# MAX32600 register map
File version: 1.0
Registers are 32-bit, read-write, reset 0x0 unless marked. A register's access mark holds for its fields unless they carry their own. Offsets are from the block's base; [hi:lo] are bit positions; {n}, {i} and the like mark numbered series.

## DAC0 — DAC (DAC0-12bit, DAC1-12bit, DAC2-8bit, DAC3-8bit)
Base 0x40050000
Same registers: DAC1 0x40051000, DAC2 0x40052000, DAC3 0x40053000
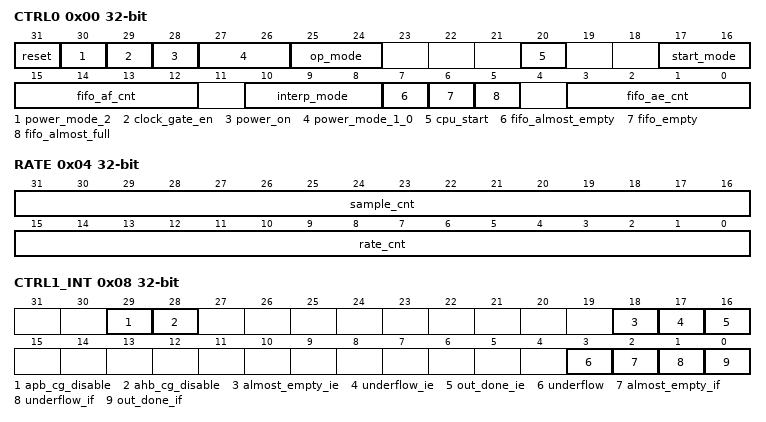
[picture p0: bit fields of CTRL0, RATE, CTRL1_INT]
0x00 CTRL0 — DAC Control Register 0
  [31] reset — DAC Reset
  [30] power_mode_2 — DAC Power Mode (bit 2)
  [29] clock_gate_en — DAC Interface Clock Gate Enable
  [28] power_on — DAC Power On Enable
  [27:26] power_mode_1_0 — DAC Power Mode (bits 1 and 0)
  [25:24] op_mode — DAC Operation Mode
  [20] cpu_start — DAC Output CPU Start
  [17:16] start_mode — DAC Output Start Mode
  [15:12] fifo_af_cnt — DAC FIFO Almost Full Threshold
  [10:8] interp_mode — DAC Output Interpolation Mode
  [7] fifo_almost_empty ro — DAC FIFO Almost Empty Flag
  [6] fifo_empty ro — DAC FIFO Empty Flag
  [5] fifo_almost_full ro — DAC FIFO Almost Full Flag
  [3:0] fifo_ae_cnt — DAC FIFO Almost Empty Threshold
0x04 RATE — DAC Output Rate/Sample Control
  [31:16] sample_cnt — DAC Output Sample Count
  [15:0] rate_cnt — DAC Output Rate Control
0x08 CTRL1_INT — DAC Control Register 1, Interrupt Flags and Enable/Disable
  [29] apb_cg_disable — Local APB dynamic clock gate disable
  [28] ahb_cg_disable — Local AHB dynamic clock gate disable
  [18] almost_empty_ie — FIFO Almost Empty Interrupt Enable
  [17] underflow_ie — FIFO Underflow Interrupt Enable
  [16] out_done_ie — DAC Output Done Interrupt Enable
  [3] underflow ro — FIFO Underflow Status
  [2] almost_empty_if write-1-clears — FIFO Almost Empty Interrupt Flag
  [1] underflow_if write-1-clears — FIFO Underflow Interrupt Flag
  [0] out_done_if write-1-clears — DAC Output Done Interrupt Flag

## ADC
Base 0x40054000
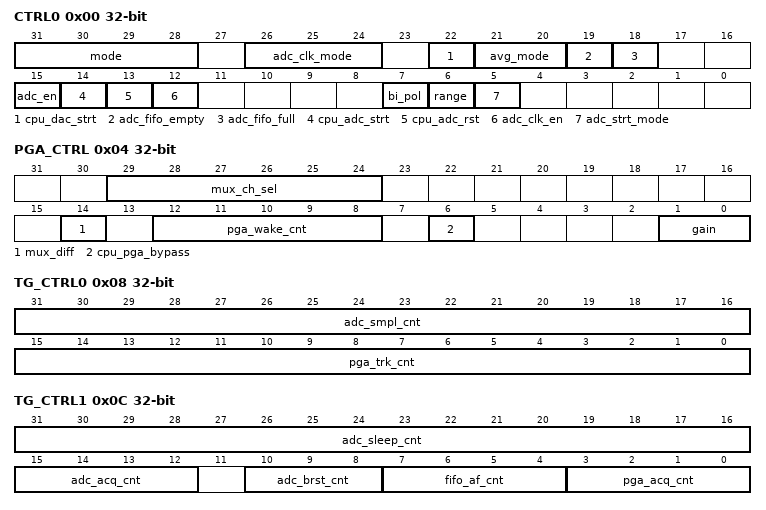
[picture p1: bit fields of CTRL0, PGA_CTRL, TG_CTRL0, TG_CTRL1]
0x00 CTRL0 — ADC Control Register 0
  [31:28] mode — ADC Operating Mode
  [26:24] adc_clk_mode — ADC Clock Mode
  [22] cpu_dac_strt — CPU DAC Sequence Start
  [21:20] avg_mode — ADC Decimation Filter Mode
  [19] adc_fifo_empty ro — ADC FIFO Empty Flag
  [18] adc_fifo_full ro — ADC FIFO Almost Full Warning
  [15] adc_en — CPU ADC Enable
  [14] cpu_adc_strt — CPU Start for ADC Data Collection
  [13] cpu_adc_rst — CPU ADC Reset
  [12] adc_clk_en — ADC Interface Clock Enable
  [7] bi_pol — ADC Unipolar/Bipolar Mode Select
  [6] range — ADC Range Control (Bipolar Mode Only)
  [5] adc_strt_mode — ADC Start Mode Control
0x04 PGA_CTRL — PGA Control Register
  [29:24] mux_ch_sel — ADC Input Mux Select
  [14] mux_diff — Differential ADC Mux Select
  [12:8] pga_wake_cnt — PGA Wakeup Counter
  [6] cpu_pga_bypass — PGA Bypass Control
  [1:0] gain — PGA Gain Setting
0x08 TG_CTRL0 — ADC Timing Generator Control 0
  [31:16] adc_smpl_cnt — ADC Sample Count
  [15:0] pga_trk_cnt — PGA Track Window Count
0x0C TG_CTRL1 — ADC Timing Generator Control 1
  [31:16] adc_sleep_cnt — ADC Sleep Count
  [15:12] adc_acq_cnt — ADC Acquisition Window Count
  [10:8] adc_brst_cnt — ADC Burst Count Setting
  [7:4] fifo_af_cnt — ADC FIFO Almost Full Threshold Control
  [3:0] pga_acq_cnt — PGA Acquisition Window Count
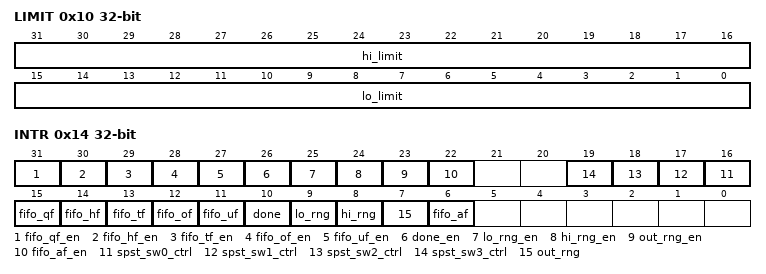
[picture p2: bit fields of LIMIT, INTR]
0x10 LIMIT — ADC Limit Settings
  [31:16] hi_limit — ADC Sample Upper Limit
  [15:0] lo_limit — ADC Sample Lower Limit
0x14 INTR — ADC Interrupt Flags and Enable/Disable Controls
  [31] fifo_qf_en — ADC FIFO One-Quarter Full Interrupt Enable
  [30] fifo_hf_en — ADC FIFO Half Full Interrupt Enable
  [29] fifo_tf_en — ADC FIFO Three-Quarters Full Interrupt Enable
  [28] fifo_of_en — ADC FIFO Overflow Interrupt Enable
  [27] fifo_uf_en — ADC FIFO Underflow Interrupt Enable
  [26] done_en — ADC Data Collection Complete Interrupt Enable
  [25] lo_rng_en — ADC Sample Below Low Limit Interrupt Enable
  [24] hi_rng_en — ADC Sample Above High Limit Interrupt Enable
  [23] out_rng_en — ADC Sample Out of Range Interrupt Enable
  [22] fifo_af_en — ADC FIFO Almost Full Interrupt Enable
  [n+16] spst_sw{n}_ctrl (n=0..3) — SPST{n} Switch Control Mode
  [15] fifo_qf write-1-clears — ADC FIFO One-Quarter Full Interrupt Flag
  [14] fifo_hf write-1-clears — ADC FIFO Half Full Interrupt Flag
  [13] fifo_tf write-1-clears — ADC FIFO Three-Quarters Full Interrupt Flag
  [12] fifo_of write-1-clears — ADC FIFO Overflow Interrupt Flag
  [11] fifo_uf write-1-clears — ADC FIFO Underflow Interrupt Flag
  [10] done write-1-clears — ADC Data Collection Complete Interrupt Flag
  [9] lo_rng write-1-clears — ADC Sample Below Low Limit Interrupt Flag
  [8] hi_rng write-1-clears — ADC Sample Above High Limit Interrupt Flag
  [7] out_rng write-1-clears — ADC Sample Out of Range Interrupt Flag
  [6] fifo_af ro — ADC FIFO Almost Full Interrupt Flag
0x18 OUT — ADC Output Register
  [15:0] data_reg ro — ADC Current Valid Data Sample
